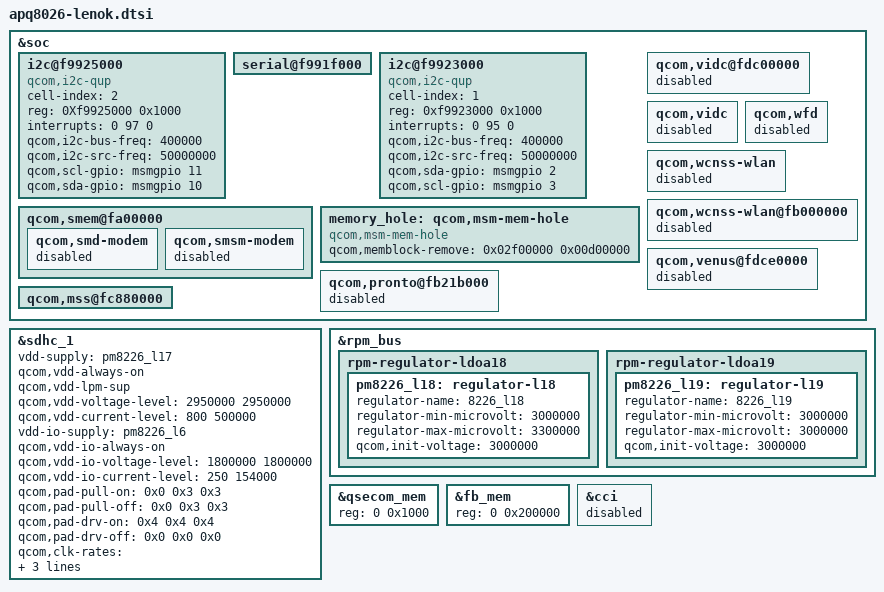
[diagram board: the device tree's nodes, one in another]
/* Copyright (c) 2014, LGE Inc. All rights reserved.
 *
 * This program is free software; you can redistribute it and/or modify
 * it under the terms of the GNU General Public License version 2 and
 * only version 2 as published by the Free Software Foundation.
 *
 * This program is distributed in the hope that it will be useful,
 * but WITHOUT ANY WARRANTY; without even the implied warranty of
 * MERCHANTABILITY or FITNESS FOR A PARTICULAR PURPOSE.  See the
 * GNU General Public License for more details.
 */

#include "../qcom/msm8226.dtsi"
#include "../qcom/apq8026-v2.dtsi"
#include "apq8026-lenok-memory.dtsi"
#include "../qcom/msm8226-w-qseecom.dtsi"
#include "../qcom/msm8226-v2-pm.dtsi"
#include "apq8026-lenok-panel.dtsi"
#include "apq8026-lenok-sensor.dtsi"
#include "apq8026-lenok-usb.dtsi"
#include "apq8026-lenok-misc.dtsi"
#include "apq8026-lenok-pm.dtsi"
#include "apq8026-lenok-input.dtsi"
#include "apq8026-lenok-bt.dtsi"
#include "apq8026-lenok-sound.dtsi"

&soc {
	i2c@f9925000 { /* BLSP1 QUP3 */
		cell-index = <2>;
		compatible = "qcom,i2c-qup";
		reg = <0Xf9925000 0x1000>;
		#address-cells = <1>;
		#size-cells = <0>;
		reg-names = "qup_phys_addr";
		interrupts = <0 97 0>;
		interrupt-names = "qup_err_intr";
		qcom,i2c-bus-freq = <400000>;
		qcom,i2c-src-freq = <50000000>;
		qcom,scl-gpio = <&msmgpio 11 0>;
		qcom,sda-gpio = <&msmgpio 10 0>;
	};

	serial@f991f000 {
		status = "ok";
	};

	i2c@f9923000 { /* BLSP-1 QUP-1 */
		cell-index = <1>;
		compatible = "qcom,i2c-qup";
		reg = <0xf9923000 0x1000>;
		#address-cells = <1>;
		#size-cells = <0>;
		reg-names = "qup_phys_addr";
		interrupts = <0 95 0>;
		interrupt-names = "qup_err_intr";
		qcom,i2c-bus-freq = <400000>;
		qcom,i2c-src-freq = <50000000>;
		qcom,sda-gpio = <&msmgpio 2 0>;
		qcom,scl-gpio = <&msmgpio 3 0>;
	};

	qcom,smem@fa00000 {
		qcom,smd-modem {
			status = "disabled";
		};
		qcom,smsm-modem {
			status = "disabled";
		};
	};

	memory_hole: qcom,msm-mem-hole {
		compatible = "qcom,msm-mem-hole";
		qcom,memblock-remove = <0x02f00000 0x00d00000>;
	};

	qcom,vidc@fdc00000 {
		status = "disabled";
	};
	qcom,vidc {
		status = "disabled";
	};
	qcom,wfd {
		status = "disabled";
	};
	qcom,wcnss-wlan {
		status = "disabled";
	};
	qcom,wcnss-wlan@fb000000 {
		status = "disabled";
	};
	qcom,venus@fdce0000 {
		status = "disabled";
	};
	qcom,pronto@fb21b000 {
		status = "disabled";
	};
	qcom,mss@fc880000 {
		/delete-property/ qcom,gpio-err-fatal;
		/delete-property/ qcom,gpio-err-ready;
		/delete-property/ qcom,gpio-proxy-unvote;
		/delete-property/ qcom,gpio-stop-ack;
		/delete-property/ qcom,gpio-force-stop;
	};
};

&sdhc_1 {
	vdd-supply = <&pm8226_l17>;
	qcom,vdd-always-on;
	qcom,vdd-lpm-sup;
	qcom,vdd-voltage-level = <2950000 2950000>;
	qcom,vdd-current-level = <800 500000>;

	vdd-io-supply = <&pm8226_l6>;
	qcom,vdd-io-always-on;
	qcom,vdd-io-voltage-level = <1800000 1800000>;
	qcom,vdd-io-current-level = <250 154000>;

	qcom,pad-pull-on = <0x0 0x3 0x3>; /* no-pull, pull-up, pull-up */
	qcom,pad-pull-off = <0x0 0x3 0x3>; /* no-pull, pull-up, pull-up */
	qcom,pad-drv-on = <0x4 0x4 0x4>; /* 10mA, 10mA, 10mA */
	qcom,pad-drv-off = <0x0 0x0 0x0>; /* 2mA, 2mA, 2mA */

	qcom,clk-rates = <400000 25000000 50000000 100000000 200000000>;
	qcom,bus-speed-mode = "HS200_1p8v", "DDR_1p8v";
	qcom,nonremovable;

	status = "ok";
};

&rpm_bus {
	rpm-regulator-ldoa18 {
		status = "okay";
		pm8226_l18: regulator-l18 {
			regulator-name = "8226_l18";
			regulator-min-microvolt = <3000000>;
			regulator-max-microvolt = <3300000>;
			qcom,init-voltage = <3000000>;
			status = "okay";
		};
	};

	rpm-regulator-ldoa19 {
		status = "okay";
		pm8226_l19: regulator-l19 {
			regulator-name = "8226_l19";
			regulator-min-microvolt = <3000000>;
			regulator-max-microvolt = <3000000>;
			qcom,init-voltage = <3000000>;
			status = "okay";
		};
	};
};

&qsecom_mem {
	reg = <0 0x1000>;
};

&fb_mem {
	reg = <0 0x200000>;
};

&cci {
	status = "disabled";
};
